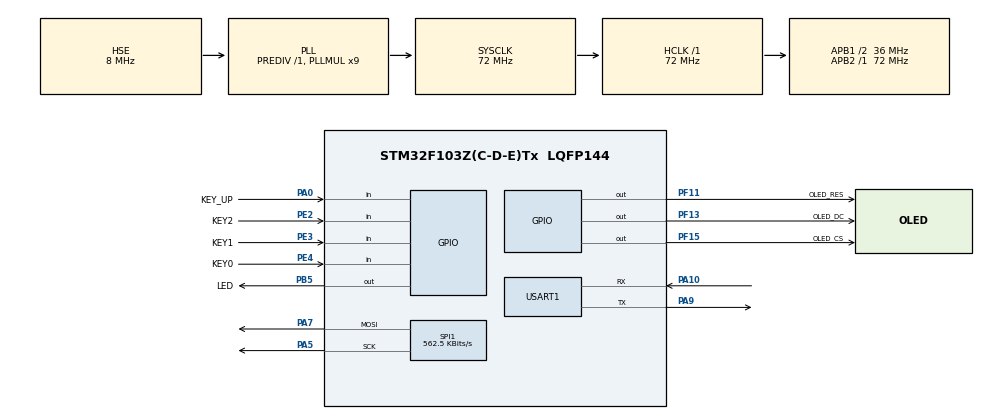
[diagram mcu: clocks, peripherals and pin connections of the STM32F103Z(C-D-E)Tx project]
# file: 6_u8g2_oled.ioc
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Mcu.Family=STM32F1
Mcu.Name=STM32F103Z(C-D-E)Tx
Mcu.Package=LQFP144
NVIC.PriorityGroup=NVIC_PRIORITYGROUP_4
OSC_IN.Mode=HSE-External-Oscillator
OSC_IN.Signal=RCC_OSC_IN
OSC_OUT.Mode=HSE-External-Oscillator
OSC_OUT.Signal=RCC_OSC_OUT
PA0-WKUP.GPIO_Label=KEY_UP
PA0-WKUP.GPIO_PuPd=GPIO_PULLDOWN
PA0-WKUP.Signal=GPIO_Input
PA10.Mode=Asynchronous
PA10.Signal=USART1_RX
PA13.Mode=Serial_Wire
PA13.Signal=SYS_JTMS-SWDIO
PA14.Mode=Serial_Wire
PA14.Signal=SYS_JTCK-SWCLK
PA5.Mode=TX_Only_Simplex_Unidirect_Master
PA5.Signal=SPI1_SCK
PA7.Mode=TX_Only_Simplex_Unidirect_Master
PA7.Signal=SPI1_MOSI
PA9.Mode=Asynchronous
PA9.Signal=USART1_TX
PB5.GPIO_Label=LED
PB5.Signal=GPIO_Output
PE2.GPIO_Label=KEY2
PE2.GPIO_PuPd=GPIO_PULLUP
PE2.Signal=GPIO_Input
PE3.GPIO_Label=KEY1
PE3.GPIO_PuPd=GPIO_PULLUP
PE3.Signal=GPIO_Input
PE4.GPIO_Label=KEY0
PE4.GPIO_PuPd=GPIO_PULLUP
PE4.Signal=GPIO_Input
PF11.GPIO_Label=OLED_RES
PF11.Signal=GPIO_Output
PF13.GPIO_Label=OLED_DC
PF13.Signal=GPIO_Output
PF15.GPIO_Label=OLED_CS
PF15.Signal=GPIO_Output
ProjectManager.HeapSize=0x200
ProjectManager.StackSize=0x400
ProjectManager.TargetToolchain=Makefile
RCC.AHBFreq_Value=72000000
RCC.APB1CLKDivider=RCC_HCLK_DIV2
RCC.APB1Freq_Value=36000000
RCC.APB1TimFreq_Value=72000000
RCC.APB2Freq_Value=72000000
RCC.APB2TimFreq_Value=72000000
RCC.HCLKFreq_Value=72000000
RCC.PLLMUL=RCC_PLL_MUL9
RCC.PLLSourceVirtual=RCC_PLLSOURCE_HSE
RCC.SYSCLKFreq_VALUE=72000000
RCC.SYSCLKSource=RCC_SYSCLKSOURCE_PLLCLK
RCC.USBFreq_Value=72000000
SPI1.BaudRatePrescaler=SPI_BAUDRATEPRESCALER_128
SPI1.CalculateBaudRate=562.5 KBits/s
SPI1.Direction=SPI_DIRECTION_2LINES
SPI1.Mode=SPI_MODE_MASTER
SPI1.VirtualType=VM_MASTER
USART1.VirtualMode=VM_ASYNC
board=custom

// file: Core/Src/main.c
/* USER CODE BEGIN Header */
/**
  ******************************************************************************
  * @file           : main.c
  * @brief          : Main program body
  ******************************************************************************
  * @attention
  *
  * Copyright (c) 2025 STMicroelectronics.
  * All rights reserved.
  *
  * This software is licensed under terms that can be found in the LICENSE file
  * in the root directory of this software component.
  * If no LICENSE file comes with this software, it is provided AS-IS.
  *
  ******************************************************************************
  */
/* USER CODE END Header */
#include "main.h"
#include "spi.h"
#include "usart.h"
#include "gpio.h"

/* USER CODE BEGIN Includes */
#include "oled.h"
#include "u8g2.h"
/* USER CODE END Includes */

/* USER CODE BEGIN PV */
extern u8g2_t u8g2; // OLED display context

/* USER CODE END PV */

void SystemClock_Config(void);

int main(void)
{

  /* MCU Configuration--------------------------------------------------------*/

  /* Reset of all peripherals, Initializes the Flash interface and the Systick. */
  HAL_Init();

  /* Configure the system clock */
  SystemClock_Config();

  /* Initialize all configured peripherals */
  MX_GPIO_Init();
  MX_USART1_UART_Init();
  MX_SPI1_Init();
  /* USER CODE BEGIN 2 */
  oled_init(); // 初始�? OLED 显示
  HAL_Delay(1000); // 等待 OLED 初始化完�?

  /* USER CODE END 2 */

  /* Infinite loop */
  while (1)
  {

    /* USER CODE BEGIN 3 */
    //oled_draw_test(); // 绘制测试图像
    //demo(&u8g2);
    mui_all();
    // astra_ui_widget_core();
    // astra_ui_main_core();
    // ad_astra();

    }
  /* USER CODE END 3 */
}

void SystemClock_Config(void)
{
  RCC_OscInitTypeDef RCC_OscInitStruct = {0};
  RCC_ClkInitTypeDef RCC_ClkInitStruct = {0};

  /** Initializes the RCC Oscillators according to the specified parameters
  * in the RCC_OscInitTypeDef structure.
  */
  RCC_OscInitStruct.OscillatorType = RCC_OSCILLATORTYPE_HSE;
  RCC_OscInitStruct.HSEState = RCC_HSE_ON;
  RCC_OscInitStruct.HSEPredivValue = RCC_HSE_PREDIV_DIV1;
  RCC_OscInitStruct.HSIState = RCC_HSI_ON;
  RCC_OscInitStruct.PLL.PLLState = RCC_PLL_ON;
  RCC_OscInitStruct.PLL.PLLSource = RCC_PLLSOURCE_HSE;
  RCC_OscInitStruct.PLL.PLLMUL = RCC_PLL_MUL9;
  if (HAL_RCC_OscConfig(&RCC_OscInitStruct) != HAL_OK)
  {
    Error_Handler();
  }

  /** Initializes the CPU, AHB and APB buses clocks
  */
  RCC_ClkInitStruct.ClockType = RCC_CLOCKTYPE_HCLK|RCC_CLOCKTYPE_SYSCLK
                              |RCC_CLOCKTYPE_PCLK1|RCC_CLOCKTYPE_PCLK2;
  RCC_ClkInitStruct.SYSCLKSource = RCC_SYSCLKSOURCE_PLLCLK;
  RCC_ClkInitStruct.AHBCLKDivider = RCC_SYSCLK_DIV1;
  RCC_ClkInitStruct.APB1CLKDivider = RCC_HCLK_DIV2;
  RCC_ClkInitStruct.APB2CLKDivider = RCC_HCLK_DIV1;

  if (HAL_RCC_ClockConfig(&RCC_ClkInitStruct, FLASH_LATENCY_2) != HAL_OK)
  {
    Error_Handler();
  }
}

void Error_Handler(void)
{
  __disable_irq();
  while (1)
  {
  }
}
